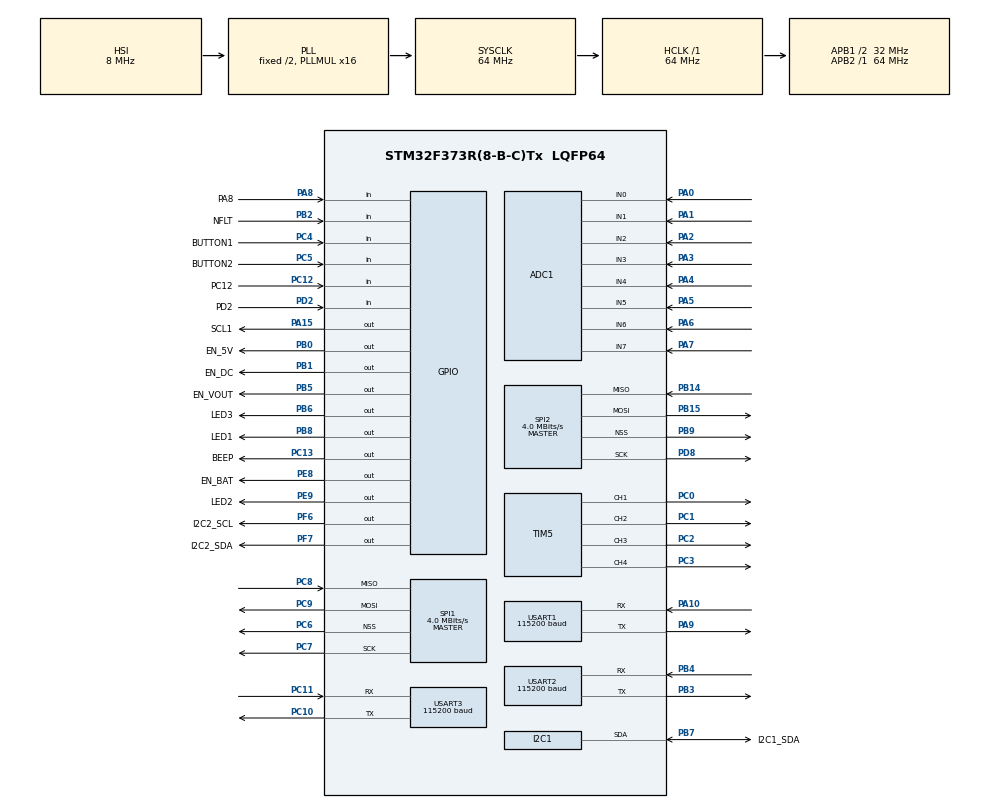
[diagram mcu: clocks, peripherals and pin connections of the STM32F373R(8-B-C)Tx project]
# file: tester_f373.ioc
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ADC1.Channel-25\#ChannelRegularConversion=ADC_CHANNEL_0
ADC1.Channel-26\#ChannelRegularConversion=ADC_CHANNEL_1
ADC1.Channel-27\#ChannelRegularConversion=ADC_CHANNEL_2
ADC1.Channel-28\#ChannelRegularConversion=ADC_CHANNEL_3
ADC1.Channel-29\#ChannelRegularConversion=ADC_CHANNEL_4
ADC1.Channel-30\#ChannelRegularConversion=ADC_CHANNEL_5
ADC1.Channel-31\#ChannelRegularConversion=ADC_CHANNEL_6
ADC1.Channel-32\#ChannelRegularConversion=ADC_CHANNEL_7
ADC1.ContinuousConvMode=DISABLE
ADC1.DiscontinuousConvMode=ENABLE
ADC1.EnableRegularConversion=ENABLE
ADC1.InjNumberOfConversion=0
ADC1.NbrOfConversion=8
ADC1.NbrOfConversionFlag=1
ADC1.Rank-25\#ChannelRegularConversion=1
ADC1.Rank-26\#ChannelRegularConversion=2
ADC1.Rank-27\#ChannelRegularConversion=3
ADC1.Rank-28\#ChannelRegularConversion=4
ADC1.Rank-29\#ChannelRegularConversion=5
ADC1.Rank-30\#ChannelRegularConversion=6
ADC1.Rank-31\#ChannelRegularConversion=7
ADC1.Rank-32\#ChannelRegularConversion=8
ADC1.SamplingTime-25\#ChannelRegularConversion=ADC_SAMPLETIME_239CYCLES_5
ADC1.SamplingTime-26\#ChannelRegularConversion=ADC_SAMPLETIME_239CYCLES_5
ADC1.SamplingTime-27\#ChannelRegularConversion=ADC_SAMPLETIME_239CYCLES_5
ADC1.SamplingTime-28\#ChannelRegularConversion=ADC_SAMPLETIME_239CYCLES_5
ADC1.SamplingTime-29\#ChannelRegularConversion=ADC_SAMPLETIME_239CYCLES_5
ADC1.SamplingTime-30\#ChannelRegularConversion=ADC_SAMPLETIME_239CYCLES_5
ADC1.SamplingTime-31\#ChannelRegularConversion=ADC_SAMPLETIME_239CYCLES_5
ADC1.SamplingTime-32\#ChannelRegularConversion=ADC_SAMPLETIME_239CYCLES_5
ADC1.master=1
Mcu.Family=STM32F3
<<<<<<< HEAD
=======
>>>>>>> b016ac5b4b5111c44bb4d4d95b5c861d95950986
Mcu.Name=STM32F373R(8-B-C)Tx
Mcu.Package=LQFP64
NVIC.PriorityGroup=NVIC_PRIORITYGROUP_4
NVIC.SPI1_IRQn=true\:0\:0\:false\:false\:true\:true\:true\:true
NVIC.SPI2_IRQn=true\:0\:0\:false\:false\:true\:true\:true\:true
NVIC.USART1_IRQn=true\:0\:0\:false\:false\:true\:true\:true\:true
NVIC.USART2_IRQn=true\:0\:0\:false\:false\:true\:true\:true\:true
NVIC.USART3_IRQn=true\:0\:0\:false\:false\:true\:true\:true\:true
PA0.Mode=IN0
PA0.Signal=ADC1_IN0
PA1.Mode=IN1
PA1.Signal=ADC1_IN1
PA10.Mode=Asynchronous
PA10.Signal=USART1_RX
PA13.Mode=Serial_Wire
PA13.Signal=SYS_JTMS-SWDIO
PA14.Mode=Serial_Wire
PA14.Signal=SYS_JTCK-SWCLK
PA15.GPIO_Label=SCL1
PA15.Signal=GPIO_Output
PA2.Mode=IN2
PA2.Signal=ADC1_IN2
PA3.Mode=IN3
PA3.Signal=ADC1_IN3
PA4.Mode=IN4
PA4.Signal=ADC1_IN4
PA5.Mode=IN5
PA5.Signal=ADC1_IN5
PA6.Mode=IN6
PA6.Signal=ADC1_IN6
PA7.Mode=IN7
PA7.Signal=ADC1_IN7
PA8.GPIO_Label=PA8
PA8.Signal=GPIO_Input
PA9.Mode=Asynchronous
PA9.Signal=USART1_TX
PB0.GPIO_Label=EN_5V
PB0.Signal=GPIO_Output
PB1.GPIO_Label=EN_DC
PB1.Signal=GPIO_Output
PB14.Mode=Full_Duplex_Master
PB14.Signal=SPI2_MISO
PB15.Mode=Full_Duplex_Master
PB15.Signal=SPI2_MOSI
PB2.GPIO_Label=NFLT
PB2.Signal=GPIO_Input
PB3.Mode=Asynchronous
PB3.Signal=USART2_TX
PB4.Mode=Asynchronous
PB4.Signal=USART2_RX
PB5.GPIO_Label=EN_VOUT
PB5.Signal=GPIO_Output
PB6.GPIO_Label=LED3
PB6.Signal=GPIO_Output
<<<<<<< HEAD
PB7.GPIO_Label=SDA1
PB7.Signal=GPIO_Output
=======
PB7.GPIO_Label=I2C1_SDA
PB7.Mode=I2C
PB7.Signal=I2C1_SDA
>>>>>>> b016ac5b4b5111c44bb4d4d95b5c861d95950986
PB8.GPIO_Label=LED1
PB8.Signal=GPIO_Output
PB9.Mode=NSS_Signal_Hard_Output
PB9.Signal=SPI2_NSS
PC0.Signal=S_TIM5_CH1_ETR
PC1.Signal=S_TIM5_CH2
PC10.Mode=Asynchronous
PC10.Signal=USART3_TX
PC11.Mode=Asynchronous
PC11.Signal=USART3_RX
PC12.GPIO_Label=PC12
PC12.Signal=GPIO_Input
PC13.GPIO_Label=BEEP
PC13.Signal=GPIO_Output
PC2.Signal=S_TIM5_CH3
PC3.Signal=S_TIM5_CH4
PC4.GPIO_Label=BUTTON1
PC4.Signal=GPIO_Input
PC5.GPIO_Label=BUTTON2
PC5.Signal=GPIO_Input
PC6.Mode=NSS_Signal_Hard_Output
PC6.Signal=SPI1_NSS
PC7.Mode=Full_Duplex_Master
PC7.Signal=SPI1_SCK
PC8.Mode=Full_Duplex_Master
PC8.Signal=SPI1_MISO
PC9.Mode=Full_Duplex_Master
PC9.Signal=SPI1_MOSI
PD2.GPIO_Label=PD2
PD2.Signal=GPIO_Input
PD8.Mode=Full_Duplex_Master
PD8.Signal=SPI2_SCK
PE8.GPIO_Label=EN_BAT
PE8.Signal=GPIO_Output
PE9.GPIO_Label=LED2
PE9.Signal=GPIO_Output
<<<<<<< HEAD
PF6.GPIO_Label=SCL2
=======
PF6.GPIO_Label=I2C2_SCL
>>>>>>> b016ac5b4b5111c44bb4d4d95b5c861d95950986
PF6.GPIO_ModeDefaultOutputPP=GPIO_MODE_OUTPUT_OD
PF6.GPIO_PuPd=GPIO_NOPULL
PF6.Signal=GPIO_Output
<<<<<<< HEAD
PF7.GPIO_Label=SDA2
=======
PF7.GPIO_Label=I2C2_SDA
>>>>>>> b016ac5b4b5111c44bb4d4d95b5c861d95950986
PF7.GPIO_ModeDefaultOutputPP=GPIO_MODE_OUTPUT_OD
PF7.GPIO_PuPd=GPIO_NOPULL
PF7.Signal=GPIO_Output
ProjectManager.HeapSize=0x200
ProjectManager.StackSize=0x1000
ProjectManager.TargetToolchain=MDK-ARM V5.32
<<<<<<< HEAD
=======
>>>>>>> b016ac5b4b5111c44bb4d4d95b5c861d95950986
RCC.AHBFreq_Value=64000000
RCC.APB1CLKDivider=RCC_HCLK_DIV2
RCC.APB1Freq_Value=32000000
RCC.APB1TimFreq_Value=64000000
RCC.APB2Freq_Value=64000000
RCC.APB2TimFreq_Value=64000000
RCC.CortexFreq_Value=64000000
RCC.HCLKFreq_Value=64000000
RCC.HSE_VALUE=16000000
RCC.HSI_VALUE=8000000
RCC.LSE_VALUE=32768
RCC.PLLMUL=RCC_PLL_MUL16
RCC.SYSCLKFreq_VALUE=64000000
RCC.SYSCLKSource=RCC_SYSCLKSOURCE_PLLCLK
RCC.USBFreq_Value=64000000
SH.S_TIM5_CH1_ETR.0=TIM5_CH1,PWM Generation1 CH1
SH.S_TIM5_CH2.0=TIM5_CH2,PWM Generation2 CH2
SH.S_TIM5_CH3.0=TIM5_CH3,PWM Generation3 CH3
SH.S_TIM5_CH4.0=TIM5_CH4,PWM Generation4 CH4
SPI1.BaudRatePrescaler=SPI_BAUDRATEPRESCALER_16
SPI1.CalculateBaudRate=4.0 MBits/s
SPI1.DataSize=SPI_DATASIZE_8BIT
SPI1.Direction=SPI_DIRECTION_2LINES
SPI1.Mode=SPI_MODE_MASTER
SPI1.VirtualNSS=VM_NSSHARD
SPI1.VirtualType=VM_MASTER
SPI2.BaudRatePrescaler=SPI_BAUDRATEPRESCALER_8
SPI2.CalculateBaudRate=4.0 MBits/s
SPI2.DataSize=SPI_DATASIZE_8BIT
SPI2.Direction=SPI_DIRECTION_2LINES
SPI2.Mode=SPI_MODE_MASTER
SPI2.VirtualNSS=VM_NSSHARD
SPI2.VirtualType=VM_MASTER
TIM5.Channel-PWM\ Generation1\ CH1=TIM_CHANNEL_1
TIM5.Channel-PWM\ Generation2\ CH2=TIM_CHANNEL_2
TIM5.Channel-PWM\ Generation3\ CH3=TIM_CHANNEL_3
TIM5.Channel-PWM\ Generation4\ CH4=TIM_CHANNEL_4
USART1.BaudRate=115200
USART1.VirtualMode-Asynchronous=VM_ASYNC
USART2.BaudRate=115200
USART2.VirtualMode-Asynchronous=VM_ASYNC
USART3.BaudRate=115200
USART3.VirtualMode-Asynchronous=VM_ASYNC
VP_CRC_VS_CRC.Mode=CRC_Activate
board=custom

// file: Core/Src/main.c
/* USER CODE BEGIN Header */
/**
  ******************************************************************************
  * @file           : main.c
  * @brief          : Main program body
  ******************************************************************************
  * @attention
  *
  * Copyright (c) 2023 STMicroelectronics.
  * All rights reserved.
  *
  * This software is licensed under terms that can be found in the LICENSE file
  * in the root directory of this software component.
  * If no LICENSE file comes with this software, it is provided AS-IS.
  *
  ******************************************************************************
  */
/* USER CODE END Header */
#include "main.h"

/* USER CODE BEGIN Includes */
#include "board.h"
#include "task.h"
/* USER CODE END Includes */

ADC_HandleTypeDef hadc1;

CRC_HandleTypeDef hcrc;
<<<<<<< HEAD
=======

I2C_HandleTypeDef hi2c1;
>>>>>>> b016ac5b4b5111c44bb4d4d95b5c861d95950986

SPI_HandleTypeDef hspi1;
SPI_HandleTypeDef hspi2;

TIM_HandleTypeDef htim5;

UART_HandleTypeDef huart1;
UART_HandleTypeDef huart2;
UART_HandleTypeDef huart3;

void SystemClock_Config(void);
static void MX_GPIO_Init(void);
static void MX_ADC1_Init(void);
<<<<<<< HEAD
=======
static void MX_I2C1_Init(void);
>>>>>>> b016ac5b4b5111c44bb4d4d95b5c861d95950986
static void MX_SPI1_Init(void);
static void MX_SPI2_Init(void);
static void MX_TIM5_Init(void);
static void MX_USART1_UART_Init(void);
static void MX_USART2_UART_Init(void);
static void MX_USART3_UART_Init(void);
static void MX_CRC_Init(void);

int main(void)
{

  /* MCU Configuration--------------------------------------------------------*/

  /* Reset of all peripherals, Initializes the Flash interface and the Systick. */
  HAL_Init();

  /* Configure the system clock */
  SystemClock_Config();

  /* Initialize all configured peripherals */
  MX_GPIO_Init();
  MX_ADC1_Init();
<<<<<<< HEAD
=======
  MX_I2C1_Init();
>>>>>>> b016ac5b4b5111c44bb4d4d95b5c861d95950986
  MX_SPI1_Init();
  MX_SPI2_Init();
  MX_TIM5_Init();
  MX_USART1_UART_Init();
  MX_USART2_UART_Init();
  MX_USART3_UART_Init();
  MX_CRC_Init();
  /* USER CODE BEGIN 2 */
	boardPreInit();
	boardInit();
  /* USER CODE END 2 */

  /* Infinite loop */
  /* USER CODE BEGIN WHILE */
  while (1)
  {
      taskPolling();
    /* USER CODE END WHILE */

  }
}

void SystemClock_Config(void)
{
  RCC_OscInitTypeDef RCC_OscInitStruct = {0};
  RCC_ClkInitTypeDef RCC_ClkInitStruct = {0};
  RCC_PeriphCLKInitTypeDef PeriphClkInit = {0};

  /** Initializes the RCC Oscillators according to the specified parameters
  * in the RCC_OscInitTypeDef structure.
  */
  RCC_OscInitStruct.OscillatorType = RCC_OSCILLATORTYPE_HSI;
  RCC_OscInitStruct.HSIState = RCC_HSI_ON;
  RCC_OscInitStruct.HSICalibrationValue = RCC_HSICALIBRATION_DEFAULT;
  RCC_OscInitStruct.PLL.PLLState = RCC_PLL_ON;
  RCC_OscInitStruct.PLL.PLLSource = RCC_PLLSOURCE_HSI;
  RCC_OscInitStruct.PLL.PLLMUL = RCC_PLL_MUL16;
  if (HAL_RCC_OscConfig(&RCC_OscInitStruct) != HAL_OK)
  {
    Error_Handler();
  }

  /** Initializes the CPU, AHB and APB buses clocks
  */
  RCC_ClkInitStruct.ClockType = RCC_CLOCKTYPE_HCLK|RCC_CLOCKTYPE_SYSCLK
                              |RCC_CLOCKTYPE_PCLK1|RCC_CLOCKTYPE_PCLK2;
  RCC_ClkInitStruct.SYSCLKSource = RCC_SYSCLKSOURCE_PLLCLK;
  RCC_ClkInitStruct.AHBCLKDivider = RCC_SYSCLK_DIV1;
  RCC_ClkInitStruct.APB1CLKDivider = RCC_HCLK_DIV2;
  RCC_ClkInitStruct.APB2CLKDivider = RCC_HCLK_DIV1;

  if (HAL_RCC_ClockConfig(&RCC_ClkInitStruct, FLASH_LATENCY_2) != HAL_OK)
  {
    Error_Handler();
  }
  PeriphClkInit.PeriphClockSelection = RCC_PERIPHCLK_USART1|RCC_PERIPHCLK_USART2
<<<<<<< HEAD
                              |RCC_PERIPHCLK_USART3|RCC_PERIPHCLK_ADC1;
  PeriphClkInit.Usart1ClockSelection = RCC_USART1CLKSOURCE_PCLK2;
  PeriphClkInit.Usart2ClockSelection = RCC_USART2CLKSOURCE_PCLK1;
  PeriphClkInit.Usart3ClockSelection = RCC_USART3CLKSOURCE_PCLK1;
=======
                              |RCC_PERIPHCLK_USART3|RCC_PERIPHCLK_I2C1
                              |RCC_PERIPHCLK_ADC1;
  PeriphClkInit.Usart1ClockSelection = RCC_USART1CLKSOURCE_PCLK2;
  PeriphClkInit.Usart2ClockSelection = RCC_USART2CLKSOURCE_PCLK1;
  PeriphClkInit.Usart3ClockSelection = RCC_USART3CLKSOURCE_PCLK1;
  PeriphClkInit.I2c1ClockSelection = RCC_I2C1CLKSOURCE_HSI;
>>>>>>> b016ac5b4b5111c44bb4d4d95b5c861d95950986
  PeriphClkInit.Adc1ClockSelection = RCC_ADC1PCLK2_DIV2;

  if (HAL_RCCEx_PeriphCLKConfig(&PeriphClkInit) != HAL_OK)
  {
    Error_Handler();
  }
}

static void MX_ADC1_Init(void)
{

  ADC_ChannelConfTypeDef sConfig = {0};

  /** Common config
  */
  hadc1.Instance = ADC1;
  hadc1.Init.ScanConvMode = ADC_SCAN_ENABLE;
  hadc1.Init.ContinuousConvMode = DISABLE;
  hadc1.Init.DiscontinuousConvMode = ENABLE;
  hadc1.Init.NbrOfDiscConversion = 1;
  hadc1.Init.ExternalTrigConv = ADC_SOFTWARE_START;
  hadc1.Init.DataAlign = ADC_DATAALIGN_RIGHT;
  hadc1.Init.NbrOfConversion = 8;
  if (HAL_ADC_Init(&hadc1) != HAL_OK)
  {
    Error_Handler();
  }

  /** Configure Regular Channel
  */
  sConfig.Channel = ADC_CHANNEL_0;
  sConfig.Rank = ADC_REGULAR_RANK_1;
  sConfig.SamplingTime = ADC_SAMPLETIME_239CYCLES_5;
<<<<<<< HEAD
=======
  if (HAL_ADC_ConfigChannel(&hadc1, &sConfig) != HAL_OK)
  {
    Error_Handler();
  }

  /** Configure Regular Channel
  */
  sConfig.Channel = ADC_CHANNEL_1;
  sConfig.Rank = ADC_REGULAR_RANK_2;
  if (HAL_ADC_ConfigChannel(&hadc1, &sConfig) != HAL_OK)
  {
    Error_Handler();
  }

  /** Configure Regular Channel
  */
  sConfig.Channel = ADC_CHANNEL_2;
  sConfig.Rank = ADC_REGULAR_RANK_3;
  if (HAL_ADC_ConfigChannel(&hadc1, &sConfig) != HAL_OK)
  {
    Error_Handler();
  }

  /** Configure Regular Channel
  */
  sConfig.Channel = ADC_CHANNEL_3;
  sConfig.Rank = ADC_REGULAR_RANK_4;
  if (HAL_ADC_ConfigChannel(&hadc1, &sConfig) != HAL_OK)
  {
    Error_Handler();
  }

  /** Configure Regular Channel
  */
  sConfig.Channel = ADC_CHANNEL_4;
  sConfig.Rank = ADC_REGULAR_RANK_5;
  if (HAL_ADC_ConfigChannel(&hadc1, &sConfig) != HAL_OK)
  {
    Error_Handler();
  }

  /** Configure Regular Channel
  */
  sConfig.Channel = ADC_CHANNEL_5;
  sConfig.Rank = ADC_REGULAR_RANK_6;
  if (HAL_ADC_ConfigChannel(&hadc1, &sConfig) != HAL_OK)
  {
    Error_Handler();
  }

  /** Configure Regular Channel
  */
  sConfig.Channel = ADC_CHANNEL_6;
  sConfig.Rank = ADC_REGULAR_RANK_7;
  if (HAL_ADC_ConfigChannel(&hadc1, &sConfig) != HAL_OK)
  {
    Error_Handler();
  }

  /** Configure Regular Channel
  */
  sConfig.Channel = ADC_CHANNEL_7;
  sConfig.Rank = ADC_REGULAR_RANK_8;
>>>>>>> b016ac5b4b5111c44bb4d4d95b5c861d95950986
  if (HAL_ADC_ConfigChannel(&hadc1, &sConfig) != HAL_OK)
  {
    Error_Handler();
  }

<<<<<<< HEAD
  /** Configure Regular Channel
=======
}

static void MX_CRC_Init(void)
{

  hcrc.Instance = CRC;
  hcrc.Init.DefaultPolynomialUse = DEFAULT_POLYNOMIAL_ENABLE;
  hcrc.Init.DefaultInitValueUse = DEFAULT_INIT_VALUE_ENABLE;
  hcrc.Init.InputDataInversionMode = CRC_INPUTDATA_INVERSION_NONE;
  hcrc.Init.OutputDataInversionMode = CRC_OUTPUTDATA_INVERSION_DISABLE;
  hcrc.InputDataFormat = CRC_INPUTDATA_FORMAT_BYTES;
  if (HAL_CRC_Init(&hcrc) != HAL_OK)
  {
    Error_Handler();
  }

}

  sConfig.Channel = ADC_CHANNEL_1;
  sConfig.Rank = ADC_REGULAR_RANK_2;
  if (HAL_ADC_ConfigChannel(&hadc1, &sConfig) != HAL_OK)
  {
    Error_Handler();
  }

  /** Configure Regular Channel
  */
  sConfig.Channel = ADC_CHANNEL_2;
  sConfig.Rank = ADC_REGULAR_RANK_3;
  if (HAL_ADC_ConfigChannel(&hadc1, &sConfig) != HAL_OK)
  {
    Error_Handler();
  }

  /** Configure Regular Channel
  */
  sConfig.Channel = ADC_CHANNEL_3;
  sConfig.Rank = ADC_REGULAR_RANK_4;
  if (HAL_ADC_ConfigChannel(&hadc1, &sConfig) != HAL_OK)
  {
    Error_Handler();
  }

  /** Configure Regular Channel
  */
  sConfig.Channel = ADC_CHANNEL_4;
  sConfig.Rank = ADC_REGULAR_RANK_5;
  if (HAL_ADC_ConfigChannel(&hadc1, &sConfig) != HAL_OK)
  {
    Error_Handler();
  }

  /** Configure Regular Channel
  */
  sConfig.Channel = ADC_CHANNEL_5;
  sConfig.Rank = ADC_REGULAR_RANK_6;
  if (HAL_ADC_ConfigChannel(&hadc1, &sConfig) != HAL_OK)
  {
    Error_Handler();
  }

  /** Configure Regular Channel
  */
  sConfig.Channel = ADC_CHANNEL_6;
  sConfig.Rank = ADC_REGULAR_RANK_7;
  if (HAL_ADC_ConfigChannel(&hadc1, &sConfig) != HAL_OK)
  {
    Error_Handler();
  }

  /** Configure Regular Channel
  */
  sConfig.Channel = ADC_CHANNEL_7;
  sConfig.Rank = ADC_REGULAR_RANK_8;
  if (HAL_ADC_ConfigChannel(&hadc1, &sConfig) != HAL_OK)
  {
    Error_Handler();
  }

}

static void MX_CRC_Init(void)
{

  hcrc.Instance = CRC;
  hcrc.Init.DefaultPolynomialUse = DEFAULT_POLYNOMIAL_ENABLE;
  hcrc.Init.DefaultInitValueUse = DEFAULT_INIT_VALUE_ENABLE;
  hcrc.Init.InputDataInversionMode = CRC_INPUTDATA_INVERSION_NONE;
  hcrc.Init.OutputDataInversionMode = CRC_OUTPUTDATA_INVERSION_DISABLE;
  hcrc.InputDataFormat = CRC_INPUTDATA_FORMAT_BYTES;
  if (HAL_CRC_Init(&hcrc) != HAL_OK)
  {
    Error_Handler();
  }

}

static void MX_SPI1_Init(void)
{

  /* SPI1 parameter configuration*/
  hspi1.Instance = SPI1;
  hspi1.Init.Mode = SPI_MODE_MASTER;
  hspi1.Init.Direction = SPI_DIRECTION_2LINES;
  hspi1.Init.DataSize = SPI_DATASIZE_8BIT;
  hspi1.Init.CLKPolarity = SPI_POLARITY_LOW;
  hspi1.Init.CLKPhase = SPI_PHASE_1EDGE;
  hspi1.Init.NSS = SPI_NSS_HARD_OUTPUT;
  hspi1.Init.BaudRatePrescaler = SPI_BAUDRATEPRESCALER_16;
  hspi1.Init.FirstBit = SPI_FIRSTBIT_MSB;
  hspi1.Init.TIMode = SPI_TIMODE_DISABLE;
  hspi1.Init.CRCCalculation = SPI_CRCCALCULATION_DISABLE;
  hspi1.Init.CRCPolynomial = 7;
  hspi1.Init.CRCLength = SPI_CRC_LENGTH_DATASIZE;
  hspi1.Init.NSSPMode = SPI_NSS_PULSE_ENABLE;
  if (HAL_SPI_Init(&hspi1) != HAL_OK)
  {
    Error_Handler();
  }

}

static void MX_SPI2_Init(void)
{

  /* SPI2 parameter configuration*/
  hspi2.Instance = SPI2;
  hspi2.Init.Mode = SPI_MODE_MASTER;
  hspi2.Init.Direction = SPI_DIRECTION_2LINES;
  hspi2.Init.DataSize = SPI_DATASIZE_8BIT;
  hspi2.Init.CLKPolarity = SPI_POLARITY_LOW;
  hspi2.Init.CLKPhase = SPI_PHASE_1EDGE;
  hspi2.Init.NSS = SPI_NSS_HARD_OUTPUT;
  hspi2.Init.BaudRatePrescaler = SPI_BAUDRATEPRESCALER_8;
  hspi2.Init.FirstBit = SPI_FIRSTBIT_MSB;
  hspi2.Init.TIMode = SPI_TIMODE_DISABLE;
  hspi2.Init.CRCCalculation = SPI_CRCCALCULATION_DISABLE;
  hspi2.Init.CRCPolynomial = 7;
  hspi2.Init.CRCLength = SPI_CRC_LENGTH_DATASIZE;
  hspi2.Init.NSSPMode = SPI_NSS_PULSE_ENABLE;
  if (HAL_SPI_Init(&hspi2) != HAL_OK)
  {
    Error_Handler();
  }

}

static void MX_TIM5_Init(void)
{

  TIM_MasterConfigTypeDef sMasterConfig = {0};
  TIM_OC_InitTypeDef sConfigOC = {0};

  htim5.Instance = TIM5;
  htim5.Init.Prescaler = 0;
  htim5.Init.CounterMode = TIM_COUNTERMODE_UP;
  htim5.Init.Period = 4294967295;
  htim5.Init.ClockDivision = TIM_CLOCKDIVISION_DIV1;
  htim5.Init.AutoReloadPreload = TIM_AUTORELOAD_PRELOAD_DISABLE;
  if (HAL_TIM_PWM_Init(&htim5) != HAL_OK)
  {
    Error_Handler();
  }
  sMasterConfig.MasterOutputTrigger = TIM_TRGO_RESET;
  sMasterConfig.MasterSlaveMode = TIM_MASTERSLAVEMODE_DISABLE;
  if (HAL_TIMEx_MasterConfigSynchronization(&htim5, &sMasterConfig) != HAL_OK)
  {
    Error_Handler();
  }
  sConfigOC.OCMode = TIM_OCMODE_PWM1;
  sConfigOC.Pulse = 0;
  sConfigOC.OCPolarity = TIM_OCPOLARITY_HIGH;
  sConfigOC.OCFastMode = TIM_OCFAST_DISABLE;
  if (HAL_TIM_PWM_ConfigChannel(&htim5, &sConfigOC, TIM_CHANNEL_1) != HAL_OK)
  {
    Error_Handler();
  }
  if (HAL_TIM_PWM_ConfigChannel(&htim5, &sConfigOC, TIM_CHANNEL_2) != HAL_OK)
  {
    Error_Handler();
  }
  if (HAL_TIM_PWM_ConfigChannel(&htim5, &sConfigOC, TIM_CHANNEL_3) != HAL_OK)
  {
    Error_Handler();
  }
  if (HAL_TIM_PWM_ConfigChannel(&htim5, &sConfigOC, TIM_CHANNEL_4) != HAL_OK)
  {
    Error_Handler();
  }
  HAL_TIM_MspPostInit(&htim5);

}

static void MX_USART1_UART_Init(void)
{

  huart1.Instance = USART1;
  huart1.Init.BaudRate = 115200;
  huart1.Init.WordLength = UART_WORDLENGTH_8B;
  huart1.Init.StopBits = UART_STOPBITS_1;
  huart1.Init.Parity = UART_PARITY_NONE;
  huart1.Init.Mode = UART_MODE_TX_RX;
  huart1.Init.HwFlowCtl = UART_HWCONTROL_NONE;
  huart1.Init.OverSampling = UART_OVERSAMPLING_16;
  huart1.Init.OneBitSampling = UART_ONE_BIT_SAMPLE_DISABLE;
  huart1.AdvancedInit.AdvFeatureInit = UART_ADVFEATURE_NO_INIT;
  if (HAL_UART_Init(&huart1) != HAL_OK)
  {
    Error_Handler();
  }

}

static void MX_USART2_UART_Init(void)
{

  huart2.Instance = USART2;
  huart2.Init.BaudRate = 115200;
  huart2.Init.WordLength = UART_WORDLENGTH_8B;
  huart2.Init.StopBits = UART_STOPBITS_1;
  huart2.Init.Parity = UART_PARITY_NONE;
  huart2.Init.Mode = UART_MODE_TX_RX;
  huart2.Init.HwFlowCtl = UART_HWCONTROL_NONE;
  huart2.Init.OverSampling = UART_OVERSAMPLING_16;
  huart2.Init.OneBitSampling = UART_ONE_BIT_SAMPLE_DISABLE;
  huart2.AdvancedInit.AdvFeatureInit = UART_ADVFEATURE_NO_INIT;
  if (HAL_UART_Init(&huart2) != HAL_OK)
  {
    Error_Handler();
  }

}

static void MX_USART3_UART_Init(void)
{

  huart3.Instance = USART3;
  huart3.Init.BaudRate = 115200;
  huart3.Init.WordLength = UART_WORDLENGTH_8B;
  huart3.Init.StopBits = UART_STOPBITS_1;
  huart3.Init.Parity = UART_PARITY_NONE;
  huart3.Init.Mode = UART_MODE_TX_RX;
  huart3.Init.HwFlowCtl = UART_HWCONTROL_NONE;
  huart3.Init.OverSampling = UART_OVERSAMPLING_16;
  huart3.Init.OneBitSampling = UART_ONE_BIT_SAMPLE_DISABLE;
  huart3.AdvancedInit.AdvFeatureInit = UART_ADVFEATURE_NO_INIT;
  if (HAL_UART_Init(&huart3) != HAL_OK)
  {
    Error_Handler();
  }

}

static void MX_GPIO_Init(void)
{
  GPIO_InitTypeDef GPIO_InitStruct = {0};

  /* GPIO Ports Clock Enable */
  __HAL_RCC_GPIOC_CLK_ENABLE();
  __HAL_RCC_GPIOA_CLK_ENABLE();
  __HAL_RCC_GPIOB_CLK_ENABLE();
  __HAL_RCC_GPIOE_CLK_ENABLE();
  __HAL_RCC_GPIOD_CLK_ENABLE();
  __HAL_RCC_GPIOF_CLK_ENABLE();

  /*Configure GPIO pin Output Level */
  HAL_GPIO_WritePin(BEEP_GPIO_Port, BEEP_Pin, GPIO_PIN_RESET);

  /*Configure GPIO pin Output Level */
  HAL_GPIO_WritePin(GPIOB, EN_5V_Pin|EN_DC_Pin|EN_VOUT_Pin|LED3_Pin
                          |SDA1_Pin|LED1_Pin, GPIO_PIN_RESET);

  /*Configure GPIO pin Output Level */
  HAL_GPIO_WritePin(GPIOE, EN_BAT_Pin|LED2_Pin, GPIO_PIN_RESET);

  /*Configure GPIO pin Output Level */
<<<<<<< HEAD
  HAL_GPIO_WritePin(GPIOF, SCL2_Pin|SDA2_Pin, GPIO_PIN_RESET);

  /*Configure GPIO pin Output Level */
  HAL_GPIO_WritePin(SCL1_GPIO_Port, SCL1_Pin, GPIO_PIN_RESET);
=======
  HAL_GPIO_WritePin(GPIOF, I2C2_SCL_Pin|I2C2_SDA_Pin, GPIO_PIN_RESET);
>>>>>>> b016ac5b4b5111c44bb4d4d95b5c861d95950986

  /*Configure GPIO pin : BEEP_Pin */
  GPIO_InitStruct.Pin = BEEP_Pin;
  GPIO_InitStruct.Mode = GPIO_MODE_OUTPUT_PP;
  GPIO_InitStruct.Pull = GPIO_NOPULL;
  GPIO_InitStruct.Speed = GPIO_SPEED_FREQ_LOW;
  HAL_GPIO_Init(BEEP_GPIO_Port, &GPIO_InitStruct);

  /*Configure GPIO pins : BUTTON1_Pin BUTTON2_Pin PC12_Pin */
  GPIO_InitStruct.Pin = BUTTON1_Pin|BUTTON2_Pin|PC12_Pin;
  GPIO_InitStruct.Mode = GPIO_MODE_INPUT;
  GPIO_InitStruct.Pull = GPIO_NOPULL;
  HAL_GPIO_Init(GPIOC, &GPIO_InitStruct);

  /*Configure GPIO pins : EN_5V_Pin EN_DC_Pin EN_VOUT_Pin LED3_Pin
                           SDA1_Pin LED1_Pin */
  GPIO_InitStruct.Pin = EN_5V_Pin|EN_DC_Pin|EN_VOUT_Pin|LED3_Pin
                          |SDA1_Pin|LED1_Pin;
  GPIO_InitStruct.Mode = GPIO_MODE_OUTPUT_PP;
  GPIO_InitStruct.Pull = GPIO_NOPULL;
  GPIO_InitStruct.Speed = GPIO_SPEED_FREQ_LOW;
  HAL_GPIO_Init(GPIOB, &GPIO_InitStruct);

  /*Configure GPIO pin : NFLT_Pin */
  GPIO_InitStruct.Pin = NFLT_Pin;
  GPIO_InitStruct.Mode = GPIO_MODE_INPUT;
  GPIO_InitStruct.Pull = GPIO_NOPULL;
  HAL_GPIO_Init(NFLT_GPIO_Port, &GPIO_InitStruct);

  /*Configure GPIO pins : EN_BAT_Pin LED2_Pin */
  GPIO_InitStruct.Pin = EN_BAT_Pin|LED2_Pin;
  GPIO_InitStruct.Mode = GPIO_MODE_OUTPUT_PP;
  GPIO_InitStruct.Pull = GPIO_NOPULL;
  GPIO_InitStruct.Speed = GPIO_SPEED_FREQ_LOW;
  HAL_GPIO_Init(GPIOE, &GPIO_InitStruct);

  /*Configure GPIO pin : PA8_Pin */
  GPIO_InitStruct.Pin = PA8_Pin;
  GPIO_InitStruct.Mode = GPIO_MODE_INPUT;
  GPIO_InitStruct.Pull = GPIO_NOPULL;
  HAL_GPIO_Init(PA8_GPIO_Port, &GPIO_InitStruct);

<<<<<<< HEAD
  /*Configure GPIO pins : SCL2_Pin SDA2_Pin */
  GPIO_InitStruct.Pin = SCL2_Pin|SDA2_Pin;
=======
  /*Configure GPIO pins : I2C2_SCL_Pin I2C2_SDA_Pin */
  GPIO_InitStruct.Pin = I2C2_SCL_Pin|I2C2_SDA_Pin;
>>>>>>> b016ac5b4b5111c44bb4d4d95b5c861d95950986
  GPIO_InitStruct.Mode = GPIO_MODE_OUTPUT_OD;
  GPIO_InitStruct.Pull = GPIO_NOPULL;
  GPIO_InitStruct.Speed = GPIO_SPEED_FREQ_LOW;
  HAL_GPIO_Init(GPIOF, &GPIO_InitStruct);

<<<<<<< HEAD
  /*Configure GPIO pin : SCL1_Pin */
  GPIO_InitStruct.Pin = SCL1_Pin;
  GPIO_InitStruct.Mode = GPIO_MODE_OUTPUT_PP;
  GPIO_InitStruct.Pull = GPIO_NOPULL;
  GPIO_InitStruct.Speed = GPIO_SPEED_FREQ_LOW;
  HAL_GPIO_Init(SCL1_GPIO_Port, &GPIO_InitStruct);

=======
>>>>>>> b016ac5b4b5111c44bb4d4d95b5c861d95950986
  /*Configure GPIO pin : PD2_Pin */
  GPIO_InitStruct.Pin = PD2_Pin;
  GPIO_InitStruct.Mode = GPIO_MODE_INPUT;
  GPIO_InitStruct.Pull = GPIO_NOPULL;
  HAL_GPIO_Init(PD2_GPIO_Port, &GPIO_InitStruct);

}

void Error_Handler(void)
{
  __disable_irq();
  while (1)
  {
  }
}
